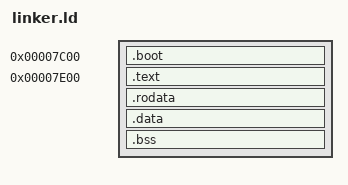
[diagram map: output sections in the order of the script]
ENTRY(_start)

SECTIONS
{
    . = 0x7C00;

    .boot : {
        *(.boot)
    }

    . = 0x7E00;

    .text : {
        *(.text)
        *(.text.*)
    }

    .rodata : {
        *(.rodata)
        *(.rodata.*)
    }

    .data : {
        *(.data)
        *(.data.*)
    }

    .bss : {
        *(.bss)
        *(.bss.*)
        *(COMMON)
    }

    /DISCARD/ : {
        *(.comment)
        *(.note.*)
        *(.eh_frame)
    }
}
